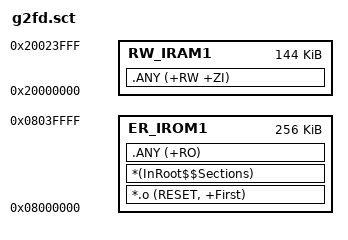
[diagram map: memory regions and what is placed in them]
; *************************************************************
; *** gs_usb_device (open-source slim build) scatter file   ***
; *************************************************************
; Standalone image at flash base — bootloader/SLIB/binInfo layout
; removed, image is linked directly at 0x08000000 (no ER_VERSION:
; version_info subsystem deleted, no compile-time version record).
;
;   0x08000000 - ...  vector table (RESET, +First) + code / RO data
;   0x20000000 ...    RW / ZI data

LR_IROM1 0x08000000 0x00040000  {
  ER_IROM1 0x08000000 0x00040000  {
   *.o (RESET, +First)
   *(InRoot$$Sections)
   .ANY (+RO)
  }
  RW_IRAM1 0x20000000 0x00024000  {
   .ANY (+RW +ZI)
  }
}
